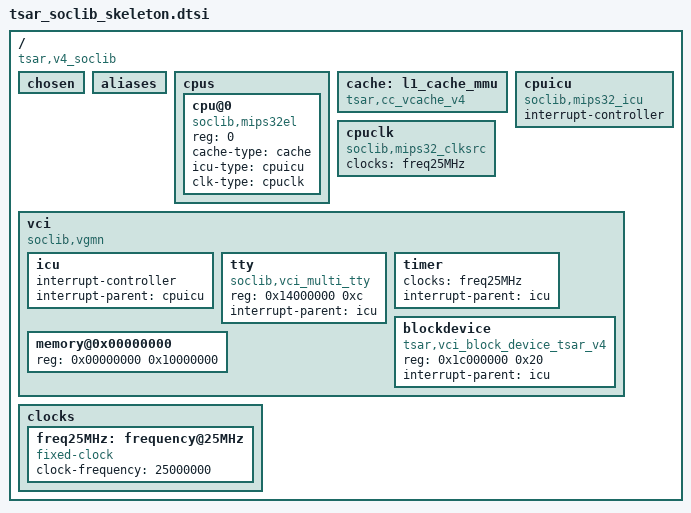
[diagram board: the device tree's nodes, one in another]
/*
 * Skeleton DTS file for TSAR on SoCLib
 */

/ {
	compatible = "tsar,v4_soclib";
	#address-cells = <1>;
	#size-cells = <1>;

	chosen { };
	aliases { };

	cpus {
		#address-cells = <1>;
		#size-cells = <0>;
		cpu@0 {
			device_type = "cpu";
			compatible = "soclib,mips32el";
			reg = <0>;
			cache-type = <&cache>;
			icu-type = <&cpuicu>;
			clk-type = <&cpuclk>;
		};
	};

	cache: l1_cache_mmu {
		compatible = "tsar,cc_vcache_v4";
	};

	cpuicu: cpuicu{
		compatible = "soclib,mips32_icu";
		interrupt-controller;
		#interrupt-cells = <1>;
	};

	cpuclk: cpuclk{
		compatible = "soclib,mips32_clksrc";
		clocks = <&freq25MHz>;
	};

	vci {
		compatible = "soclib,vgmn", "simple-bus";
		#address-cells = <1>;
		#size-cells = <1>;
		ranges; // identity mapping between root addressing and vci network

		icu: icu {
			interrupt-controller;
			interrupt-parent = <&cpuicu>;
		};

		tty: tty {
			compatible = "soclib,vci_multi_tty";
			reg = <0x14000000 0xc>;

			interrupt-parent = <&icu>;
		};

		timer {
			clocks = <&freq25MHz>;

			interrupt-parent = <&icu>;
		};

		blockdevice {
			compatible = "tsar,vci_block_device_tsar_v4";
			reg = <0x1c000000 0x20>;

			interrupt-parent = <&icu>;
		};

		/*
		framebuffer {
			compatible = "tsar,vci_framebuffer", "simple-framebuffer";
			reg = <0x20000000 (640 * 680 * 2)>;
			width = <640>;
			height = <480>;
			stride = <(640 * 2)>;
			format = "r5g6b5";
		};
		*/

		memory@0x00000000 {
			device_type = "memory";
			reg = <0x00000000 0x10000000>;
		};
	};

	clocks {
		freq25MHz: frequency@25MHz {
			#clock-cells = <0>;
			compatible = "fixed-clock";
			clock-frequency = <25000000>; // assumes a certain clock frequency
		};
	};
};
